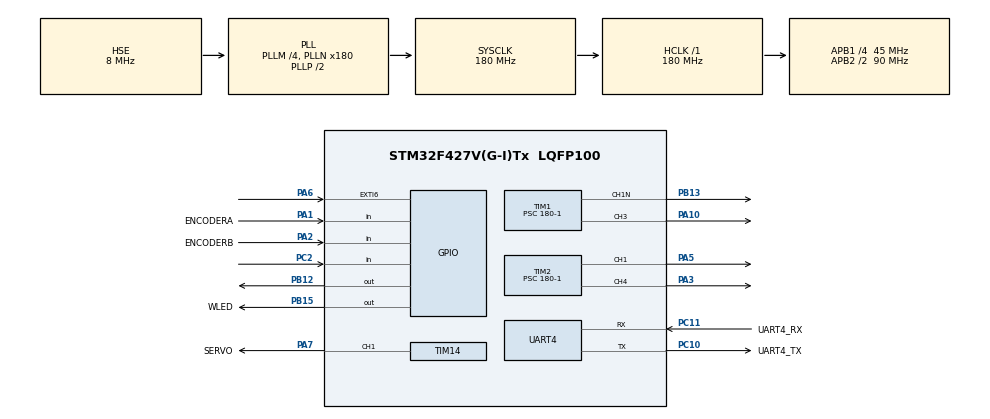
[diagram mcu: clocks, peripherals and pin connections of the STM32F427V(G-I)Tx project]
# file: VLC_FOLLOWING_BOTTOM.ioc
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Dma.Request0=UART4_TX
Dma.Request1=UART4_RX
Dma.UART4_RX.1.Direction=DMA_PERIPH_TO_MEMORY
Dma.UART4_RX.1.FIFOMode=DMA_FIFOMODE_DISABLE
Dma.UART4_RX.1.Instance=DMA1_Stream2
Dma.UART4_RX.1.MemDataAlignment=DMA_MDATAALIGN_BYTE
Dma.UART4_RX.1.MemInc=DMA_MINC_ENABLE
Dma.UART4_RX.1.Mode=DMA_NORMAL
Dma.UART4_RX.1.PeriphDataAlignment=DMA_PDATAALIGN_BYTE
Dma.UART4_RX.1.PeriphInc=DMA_PINC_DISABLE
Dma.UART4_RX.1.Priority=DMA_PRIORITY_LOW
Dma.UART4_TX.0.Direction=DMA_MEMORY_TO_PERIPH
Dma.UART4_TX.0.FIFOMode=DMA_FIFOMODE_DISABLE
Dma.UART4_TX.0.Instance=DMA1_Stream4
Dma.UART4_TX.0.MemDataAlignment=DMA_MDATAALIGN_BYTE
Dma.UART4_TX.0.MemInc=DMA_MINC_ENABLE
Dma.UART4_TX.0.Mode=DMA_NORMAL
Dma.UART4_TX.0.PeriphDataAlignment=DMA_PDATAALIGN_BYTE
Dma.UART4_TX.0.PeriphInc=DMA_PINC_DISABLE
Dma.UART4_TX.0.Priority=DMA_PRIORITY_LOW
Mcu.Family=STM32F4
Mcu.Name=STM32F427V(G-I)Tx
Mcu.Package=LQFP100
NVIC.DMA1_Stream2_IRQn=true\:0\:0\:false\:false\:true\:false\:true\:true
NVIC.DMA1_Stream4_IRQn=true\:0\:0\:false\:false\:true\:false\:true\:true
NVIC.EXTI9_5_IRQn=true\:2\:0\:true\:false\:true\:true\:true\:true
NVIC.PriorityGroup=NVIC_PRIORITYGROUP_4
NVIC.TIM4_IRQn=true\:0\:0\:false\:false\:true\:true\:true\:true
NVIC.UART4_IRQn=true\:0\:0\:false\:false\:true\:true\:true\:true
PA1.GPIO_Label=ENCODERA
PA1.Signal=GPIO_Input
PA10.Signal=S_TIM1_CH3
PA2.GPIO_Label=ENCODERB
PA2.Signal=GPIO_Input
PA3.Signal=S_TIM2_CH4
PA5.Signal=S_TIM2_CH1_ETR
PA6.GPIO_ModeDefaultEXTI=GPIO_MODE_IT_RISING_FALLING
PA6.GPIO_PuPd=GPIO_PULLDOWN
PA6.Signal=GPXTI6
PA7.GPIO_Label=SERVO
PA7.Signal=S_TIM14_CH1
PB12.GPIO_PuPd=GPIO_PULLDOWN
PB12.Signal=GPIO_Output
PB13.Mode=PWM Generation1 CH1N
PB13.Signal=TIM1_CH1N
PB15.GPIO_Label=WLED
PB15.Signal=GPIO_Output
PC10.GPIO_Label=UART4_TX
PC10.Mode=Asynchronous
PC10.Signal=UART4_TX
PC11.GPIO_Label=UART4_RX
PC11.Mode=Asynchronous
PC11.Signal=UART4_RX
PC2.Signal=GPIO_Input
PH0/OSC_IN.Mode=HSE-External-Oscillator
PH0/OSC_IN.Signal=RCC_OSC_IN
PH1/OSC_OUT.Mode=HSE-External-Oscillator
PH1/OSC_OUT.Signal=RCC_OSC_OUT
ProjectManager.HeapSize=0x200
ProjectManager.StackSize=0x400
ProjectManager.TargetToolchain=STM32CubeIDE
RCC.48MHZClocksFreq_Value=90000000
RCC.AHBFreq_Value=180000000
RCC.APB1CLKDivider=RCC_HCLK_DIV4
RCC.APB1Freq_Value=45000000
RCC.APB1TimFreq_Value=90000000
RCC.APB2CLKDivider=RCC_HCLK_DIV2
RCC.APB2Freq_Value=90000000
RCC.APB2TimFreq_Value=180000000
RCC.CortexFreq_Value=180000000
RCC.HCLKFreq_Value=180000000
RCC.HSE_VALUE=8000000
RCC.HSI_VALUE=16000000
RCC.LSE_VALUE=32768
RCC.PLLM=4
RCC.PLLN=180
RCC.PLLSourceVirtual=RCC_PLLSOURCE_HSE
RCC.SYSCLKFreq_VALUE=180000000
RCC.SYSCLKSource=RCC_SYSCLKSOURCE_PLLCLK
RCC.VCOOutputFreq_Value=360000000
SH.S_TIM14_CH1.0=TIM14_CH1,PWM Generation1 CH1
SH.S_TIM1_CH3.0=TIM1_CH3,PWM Generation3 CH3
SH.S_TIM2_CH1_ETR.0=TIM2_CH1,PWM Generation1 CH1
SH.S_TIM2_CH4.0=TIM2_CH4,PWM Generation4 CH4
TIM1.AutoReloadPreload=TIM_AUTORELOAD_PRELOAD_ENABLE
TIM1.Channel-PWM\ Generation1\ CH1N=TIM_CHANNEL_1
TIM1.Channel-PWM\ Generation3\ CH3=TIM_CHANNEL_3
TIM1.Period=10000
TIM1.Prescaler=180-1
TIM14.AutoReloadPreload=TIM_AUTORELOAD_PRELOAD_ENABLE
TIM14.Channel=TIM_CHANNEL_1
TIM14.Period=20000-1
TIM14.Prescaler=90-1
TIM2.AutoReloadPreload=TIM_AUTORELOAD_PRELOAD_ENABLE
TIM2.Channel-PWM\ Generation1\ CH1=TIM_CHANNEL_1
TIM2.Channel-PWM\ Generation4\ CH4=TIM_CHANNEL_4
TIM2.Period=10000
TIM2.Prescaler=180-1
TIM3.AutoReloadPreload=TIM_AUTORELOAD_PRELOAD_ENABLE
TIM3.Prescaler=90-1
TIM4.AutoReloadPreload=TIM_AUTORELOAD_PRELOAD_ENABLE
TIM4.Period=80-1
TIM4.Prescaler=90-1
UART4.VirtualMode=Asynchronous
VP_TIM14_VS_ClockSourceINT.Mode=Enable_Timer
VP_TIM2_VS_ClockSourceINT.Mode=Internal
VP_TIM3_VS_ClockSourceINT.Mode=Internal
VP_TIM4_VS_ClockSourceINT.Mode=Internal
board=custom

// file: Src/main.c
/* USER CODE BEGIN Header */
/**
  ******************************************************************************
  * @file           : main.c
  * @brief          : Main program body
  ******************************************************************************
  * @attention
  *
  * Copyright (c) 2023 STMicroelectronics.
  * All rights reserved.
  *
  * This software is licensed under terms that can be found in the LICENSE file
  * in the root directory of this software component.
  * If no LICENSE file comes with this software, it is provided AS-IS.
  *
  ******************************************************************************
  */
/* USER CODE END Header */
#include "main.h"
#include "dma.h"
#include "tim.h"
#include "usart.h"
#include "gpio.h"

/* USER CODE BEGIN Includes */
#include "vehicle_servo.h"
#include "vehicle_pwm_motor.h"
#include "VLC_timer.h"

/* USER CODE END Includes */

/* USER CODE BEGIN PV */
uint8_t DETECT_DATA_FLAG = 0;    // PD receives message = 1, else = 0;
uint8_t VLC_RX_DATA_BUFFER[RECEIVE_BYTES_LENGTH]; // Data buffer that stores the encoded data.
uint8_t received_data[FRAME_LENGTH];    // Original data after decoding.
/* USER CODE END PV */

void SystemClock_Config(void);

int main(void)
{

  /* MCU Configuration--------------------------------------------------------*/

  /* Reset of all peripherals, Initializes the Flash interface and the Systick. */
  HAL_Init();

  /* Configure the system clock */
  SystemClock_Config();

  /* Initialize all configured peripherals */
  MX_GPIO_Init();
  MX_DMA_Init();
  MX_UART4_Init();
  MX_TIM14_Init();
  MX_TIM3_Init();
  MX_TIM4_Init();
  MX_TIM1_Init();
  MX_TIM2_Init();
  /* USER CODE BEGIN 2 */
    VLC_timer_init();
    vehicle_servo_init();
    vehicle_pwm_motor_init();
    HAL_UART_Transmit_DMA(&huart4,"RxStart\n",8);
  /* USER CODE END 2 */

  /* Infinite loop */
  /* USER CODE BEGIN WHILE */
    while (1) {

        /**
         * The data receiving logic is in VLC_receiver.c
         */
        if(DETECT_DATA_FLAG){
            /** For debugging **/
//            HAL_UART_Transmit(&huart1,received_data,FRAME_LENGTH,HAL_MAX_DELAY);
//            HAL_UART_Transmit(&huart1,"\n",1,HAL_MAX_DELAY);

            /** Change car's state **/
            vehicle_pwm_motor_control(received_data[1]);

            /** Send the data to the upper GD32 **/
            HAL_UART_Transmit_DMA(&huart4,received_data,FRAME_LENGTH);
            DETECT_DATA_FLAG=0;
        }
    /* USER CODE END WHILE */

    }
}

void SystemClock_Config(void)
{
  RCC_OscInitTypeDef RCC_OscInitStruct = {0};
  RCC_ClkInitTypeDef RCC_ClkInitStruct = {0};

  /** Configure the main internal regulator output voltage
  */
  __HAL_RCC_PWR_CLK_ENABLE();
  __HAL_PWR_VOLTAGESCALING_CONFIG(PWR_REGULATOR_VOLTAGE_SCALE1);

  /** Initializes the RCC Oscillators according to the specified parameters
  * in the RCC_OscInitTypeDef structure.
  */
  RCC_OscInitStruct.OscillatorType = RCC_OSCILLATORTYPE_HSE;
  RCC_OscInitStruct.HSEState = RCC_HSE_ON;
  RCC_OscInitStruct.PLL.PLLState = RCC_PLL_ON;
  RCC_OscInitStruct.PLL.PLLSource = RCC_PLLSOURCE_HSE;
  RCC_OscInitStruct.PLL.PLLM = 4;
  RCC_OscInitStruct.PLL.PLLN = 180;
  RCC_OscInitStruct.PLL.PLLP = RCC_PLLP_DIV2;
  RCC_OscInitStruct.PLL.PLLQ = 4;
  if (HAL_RCC_OscConfig(&RCC_OscInitStruct) != HAL_OK)
  {
    Error_Handler();
  }

  /** Activate the Over-Drive mode
  */
  if (HAL_PWREx_EnableOverDrive() != HAL_OK)
  {
    Error_Handler();
  }

  /** Initializes the CPU, AHB and APB buses clocks
  */
  RCC_ClkInitStruct.ClockType = RCC_CLOCKTYPE_HCLK|RCC_CLOCKTYPE_SYSCLK
                              |RCC_CLOCKTYPE_PCLK1|RCC_CLOCKTYPE_PCLK2;
  RCC_ClkInitStruct.SYSCLKSource = RCC_SYSCLKSOURCE_PLLCLK;
  RCC_ClkInitStruct.AHBCLKDivider = RCC_SYSCLK_DIV1;
  RCC_ClkInitStruct.APB1CLKDivider = RCC_HCLK_DIV4;
  RCC_ClkInitStruct.APB2CLKDivider = RCC_HCLK_DIV2;

  if (HAL_RCC_ClockConfig(&RCC_ClkInitStruct, FLASH_LATENCY_5) != HAL_OK)
  {
    Error_Handler();
  }
}

void Error_Handler(void)
{
  /* USER CODE BEGIN Error_Handler_Debug */
    /* User can add his own implementation to report the HAL error return state */
    __disable_irq();
//    while (1) {
//        HAL_UART_Transmit(&huart1,"Error\n",6,HAL_MAX_DELAY);
//    }
  /* USER CODE END Error_Handler_Debug */
}
